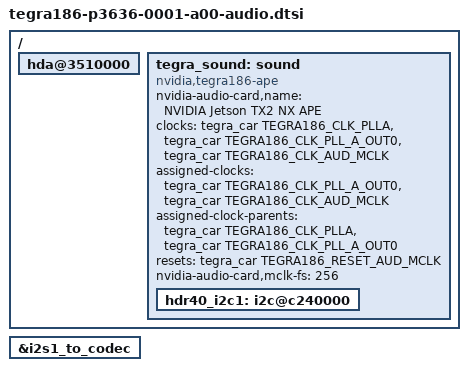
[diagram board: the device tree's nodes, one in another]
/*
 * Copyright (c) 2020, NVIDIA CORPORATION.  All rights reserved.
 *
 * This program is free software; you can redistribute it and/or modify it
 * under the terms and conditions of the GNU General Public License,
 * version 2, as published by the Free Software Foundation.
 *
 * This program is distributed in the hope it will be useful, but WITHOUT
 * ANY WARRANTY; without even the implied warranty of MERCHANTABILITY or
 * FITNESS FOR A PARTICULAR PURPOSE.  See the GNU General Public License for
 * more details.
 *
 * You should have received a copy of the GNU General Public License
 * along with this program.  If not, see <http://www.gnu.org/licenses/>.
 */

/*
 * T186 p3636-0001-a00 audio common DTSI file.
 */

#include <audio/tegra-platforms-audio-dai-links.dtsi>
#include <audio/tegra186-audio-dai-links.dtsi>

/ {
	hda@3510000 {
		status = "okay";
	};

	tegra_sound: sound {
		status = "okay";
		compatible = "nvidia,tegra186-ape";
		nvidia-audio-card,name = "NVIDIA Jetson TX2 NX APE";
		clocks = <&tegra_car TEGRA186_CLK_PLLA>,
			 <&tegra_car TEGRA186_CLK_PLL_A_OUT0>,
			 <&tegra_car TEGRA186_CLK_AUD_MCLK>;
		clock-names = "pll_a", "pll_a_out0", "extern1";
		assigned-clocks = <&tegra_car TEGRA186_CLK_PLL_A_OUT0>,
				  <&tegra_car TEGRA186_CLK_AUD_MCLK>;
		assigned-clock-parents = <&tegra_car TEGRA186_CLK_PLLA>,
					 <&tegra_car TEGRA186_CLK_PLL_A_OUT0>;
		resets = <&tegra_car TEGRA186_RESET_AUD_MCLK>;
		reset-names = "extern1_rst";

		nvidia-audio-card,mclk-fs = <256>;

		hdr40_i2c1: i2c@c240000 { };
	};
};

hdr40_snd_link_i2s: &i2s1_to_codec { };
